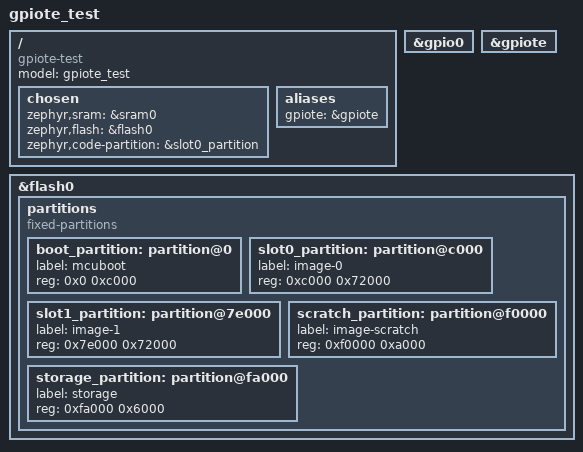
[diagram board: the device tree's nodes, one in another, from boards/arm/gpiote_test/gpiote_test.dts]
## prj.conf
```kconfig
CONFIG_GPIO=y
CONFIG_GPIO_NRFX=y
CONFIG_NRFX_GPIOTE=y
```

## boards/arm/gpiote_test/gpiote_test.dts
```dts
// Copyright (c) 2023 Nordic Semiconductor ASA
// SPDX-License-Identifier: Apache-2.0

/dts-v1/;
#include <nordic/nrf52840_qiaa.dtsi>

/ {
	model = "gpiote_test";
	compatible = "gpiote-test";

	chosen {
		zephyr,sram = &sram0;
		zephyr,flash = &flash0;
		zephyr,code-partition = &slot0_partition;
	};

	aliases {
		gpiote = &gpiote;
	};


};

&gpio0 {
	status = "okay";
};

&gpiote {
	status = "okay";
};

&flash0 {
	partitions {
		compatible = "fixed-partitions";
		#address-cells = <1>;
		#size-cells = <1>;

		boot_partition: partition@0 {
			label = "mcuboot";
			reg = <0x0 0xc000>;
		};
		slot0_partition: partition@c000 {
			label = "image-0";
			reg = <0xc000 0x72000>;
		};
		slot1_partition: partition@7e000 {
			label = "image-1";
			reg = <0x7e000 0x72000>;
		};
		scratch_partition: partition@f0000 {
			label = "image-scratch";
			reg = <0xf0000 0xa000>;
		};
		storage_partition: partition@fa000 {
			label = "storage";
			reg = <0xfa000 0x6000>;
		};
	};
};
```

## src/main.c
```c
/*
 * Copyright (c) 2012-2014 Wind River Systems, Inc.
 *
 * SPDX-License-Identifier: Apache-2.0
 */

#include <zephyr/kernel.h>
#include <zephyr/device.h>

static const struct device *const missing_device = \
	DEVICE_DT_GET(DT_ALIAS(gpiote));

void main(void)
{
	printk("Hello World! %s\n", CONFIG_BOARD);
	printk("Gpiote is ready: %d\n", device_is_ready(missing_device));
}
```
